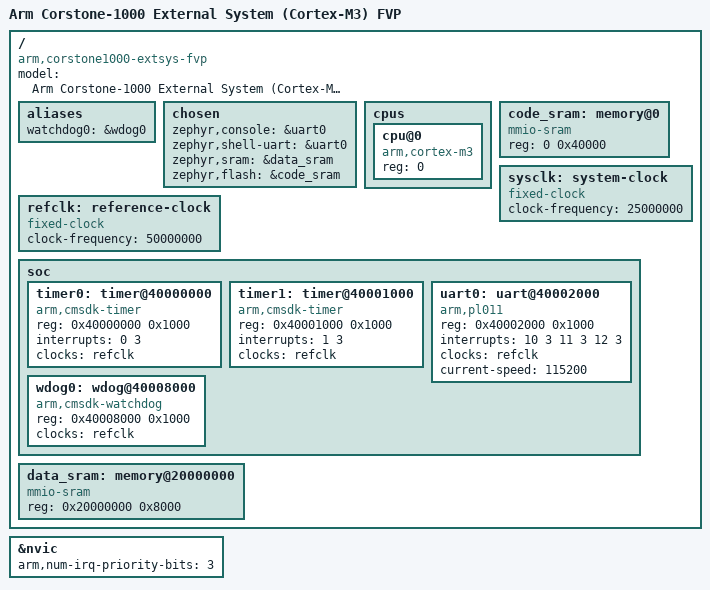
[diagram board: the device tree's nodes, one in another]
/*
 * Copyright 2026 Arm Limited and/or its affiliates <open-source-office@arm.com>
 * SPDX-License-Identifier: Apache-2.0
 */

/dts-v1/;

#include <arm/armv7-m.dtsi>

/ {
	compatible = "arm,corstone1000-extsys-fvp";
	model = "Arm Corstone-1000 External System (Cortex-M3) FVP";

	aliases {
		watchdog0 = &wdog0;
	};

	chosen {
		zephyr,console = &uart0;
		zephyr,shell-uart = &uart0;
		zephyr,sram = &data_sram;
		zephyr,flash = &code_sram;
	};

	cpus {
		#address-cells = <1>;
		#size-cells = <0>;

		cpu@0 {
			compatible = "arm,cortex-m3";
			reg = <0>;
		};
	};

	code_sram: memory@0 {
		compatible = "mmio-sram";
		reg = <0 0x40000>;
	};

	sysclk: system-clock {
		compatible = "fixed-clock";
		clock-frequency = <25000000>;
		#clock-cells = <0>;
	};

	refclk: reference-clock {
		compatible = "fixed-clock";
		clock-frequency = <50000000>;
		#clock-cells = <0>;
	};

	soc {
		timer0: timer@40000000 {
			compatible = "arm,cmsdk-timer";
			reg = <0x40000000 0x1000>;
			interrupts = <0 3>;
			clocks = <&refclk>;
		};

		timer1: timer@40001000 {
			compatible = "arm,cmsdk-timer";
			reg = <0x40001000 0x1000>;
			interrupts = <1 3>;
			clocks = <&refclk>;
		};

		uart0: uart@40002000 {
			compatible = "arm,pl011";
			reg = <0x40002000 0x1000>;
			interrupts = <10 3 11 3 12 3>;
			interrupt-names = "tx", "rx", "rxtim";
			clocks = <&refclk>;
			current-speed = <115200>;
		};

		wdog0: wdog@40008000 {
			compatible = "arm,cmsdk-watchdog";
			reg = <0x40008000 0x1000>;
			clocks = <&refclk>;
		};
	};

	data_sram: memory@20000000 {
		compatible = "mmio-sram";
		reg = <0x20000000 0x8000>;
	};
};

&nvic {
	arm,num-irq-priority-bits = <3>;
};
